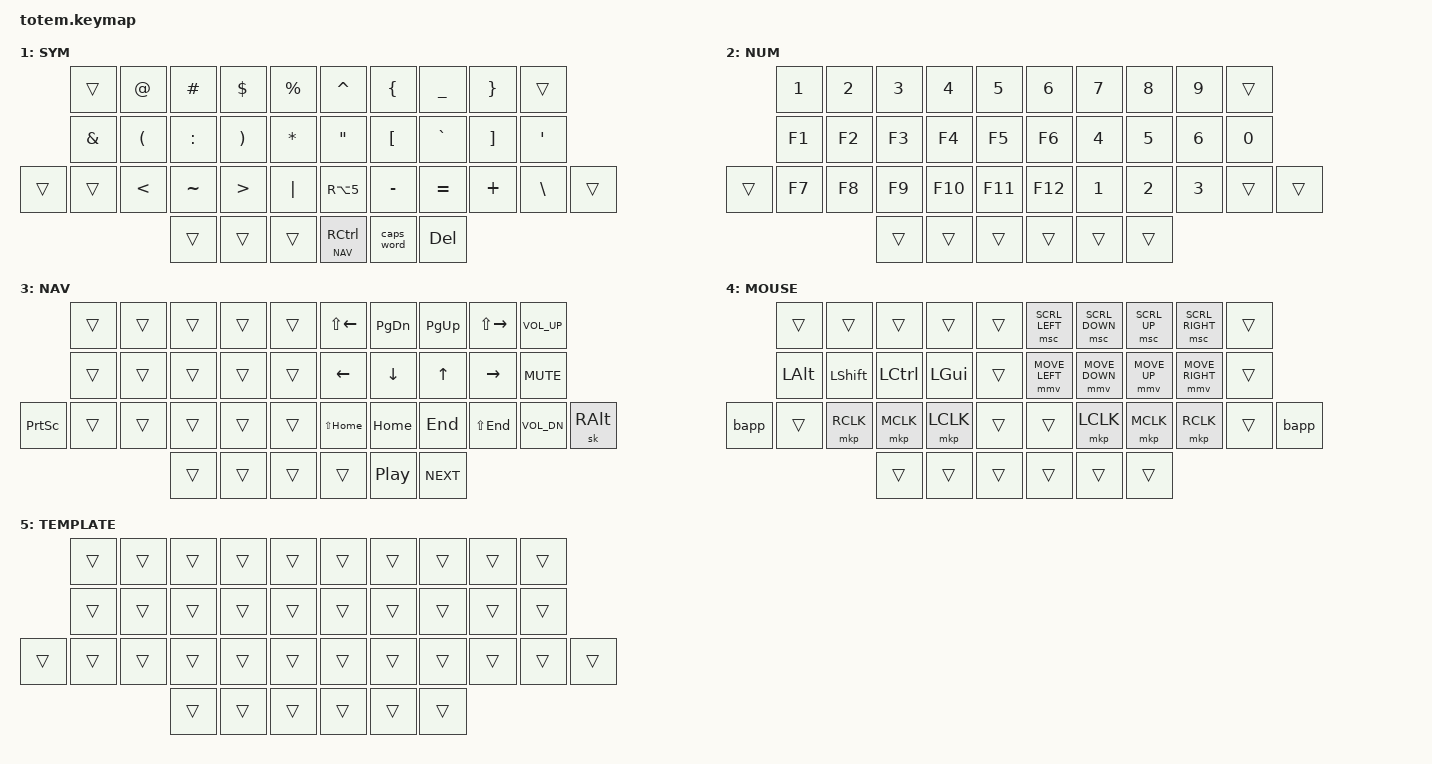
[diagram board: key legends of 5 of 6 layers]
/*
       ▀▀▀▀▀     ▀▀▀▀▀          ▀▀█▀▀
       ▄▀▀▀▄  ▄  ▄▀▀▀▄  ▄  ▄▀▀▀▄  █  ▄▀▀▀▄
       █   █  █  █   █  █  █   █  █  █   █
        ▀▀▀   █   ▀▀▀   █   ▀▀▀   ▀   ▀▀▀
              █      ▄▄▄█▄▄▄    █   █
              ▀      █  █  █     █▄█
            ▀▀▀▀▀    █  █  █      ▀
                     ▀  ▀  ▀
*/
#define ZMK_POINTING_DEFAULT_MOVE_VAL 1000  // default: 600
#define ZMK_POINTING_DEFAULT_SCRL_VAL 20    // default: 10

#include <behaviors.dtsi>
#include <dt-bindings/zmk/keys.h>
#include <dt-bindings/zmk/bt.h>
#include <dt-bindings/zmk/pointing.h>
#include <behaviors/battery_percentage_printer.dtsi>

#define VALMAK 0
#define SYM 1
#define NUM 2
#define NAV 3
#define MOUSE 4

#define XXX &none
#define ___ &trans

#define KEYS_L 0 1 2 3 4 10 11 12 13 14 20 21 22 23 24 25
#define KEYS_R 5 6 7 8 9 15 16 17 18 19 26 27 28 29 30 31
#define THUMBS_L 32 33 34
#define THUMBS_R 35 36 37
#define THUMBS THUMBS_L THUMBS_R

#define H1 LGUI
#define H2 LCTRL
#define H3 LSHFT
#define H4 LALT
#define H5 RALT
#define HRML(k1, k2, k3, k4) &hl H4 k1  &hl H3 k2  &hl H2 k3 &hl H1 k4
#define HRMR(k1, k2, k3, k4) &hr H1 k1  &hr H2 k2  &hr H3 k3 &hr H4 k4

#define QUICK_TAP_MS 200

/ {
    behaviors {
        comma: comma_morph {
            compatible = "zmk,behavior-mod-morph";
            #binding-cells = <0>;
            mods = <(MOD_LSFT | MOD_RSFT)>;
            bindings = <&kp COMMA>, <&kp SEMI>;
        };
        dot: dot_morph {
            compatible = "zmk,behavior-mod-morph";
            #binding-cells = <0>;
            mods = <(MOD_LSFT | MOD_RSFT)>;
            bindings = <&kp DOT>, <&kp QMARK>;
        };
        slash: slash_morph {
            compatible = "zmk,behavior-mod-morph";
            #binding-cells = <0>;
            mods = <(MOD_LSFT | MOD_RSFT)>;
            bindings = <&kp SLASH>, <&kp EXCL>;
        };
        skq: sticky_key_quick {
            compatible = "zmk,behavior-sticky-key";
            bindings = <&kp>;
            #binding-cells = <1>;
            quick-release; // release after the next key is pressed, not released
            release-after-ms = <1000>;
        };

        // hl and hr reuse the same settings, just hold-trigger-key-positions are different
        hl: home_row_mod_l {
            compatible = "zmk,behavior-hold-tap";
            #binding-cells = <2>;
            bindings = <&kp>, <&kp>;
            flavor = "balanced";
            tapping-term-ms = <280>;
            quick-tap-ms = <QUICK_TAP_MS>;
            require-prior-idle-ms = <200>;
            hold-trigger-on-release;
            hold-trigger-key-positions = <KEYS_R THUMBS>;
        };
        hr: home_row_mod_r {
            compatible = "zmk,behavior-hold-tap";
            #binding-cells = <2>;
            bindings = <&kp>, <&kp>;
            flavor = "balanced";
            tapping-term-ms = <280>;
            quick-tap-ms = <QUICK_TAP_MS>;
            require-prior-idle-ms = <200>;
            hold-trigger-on-release;
            hold-trigger-key-positions = <KEYS_L THUMBS>;
        };
        // regular thumb layer switch
        tl: thumb_layer_l {
            compatible = "zmk,behavior-hold-tap";
            #binding-cells = <2>;
            bindings = <&mo>, <&kp>;
            flavor = "hold-preferred";
            tapping-term-ms = <200>;
            quick-tap-ms = <QUICK_TAP_MS>;
            hold-trigger-key-positions = <KEYS_L KEYS_R THUMBS_R>;
        };
        tr: thumb_layer_r {
            compatible = "zmk,behavior-hold-tap";
            #binding-cells = <2>;
            bindings = <&mo>, <&kp>;
            flavor = "hold-preferred";
            tapping-term-ms = <200>;
            quick-tap-ms = <QUICK_TAP_MS>;
            hold-trigger-key-positions = <KEYS_L KEYS_R THUMBS_L>;
        };
        trr: thumb_layer_alpha_r {
            compatible = "zmk,behavior-hold-tap";
            #binding-cells = <2>;
            bindings = <&mo>, <&kp>;
            flavor = "balanced";
            tapping-term-ms = <200>;
            quick-tap-ms = <QUICK_TAP_MS>;
            require-prior-idle-ms = <100>;
            hold-trigger-key-positions = <KEYS_L KEYS_R THUMBS_L>;
        };
        // tls is a special thumb layer version that includes capital space to end a sentence and has alpha-like hrm
        // timings too
        tls: thumb_layer_spc {
            compatible = "zmk,behavior-hold-tap";
            #binding-cells = <2>;
            bindings = <&mo>, <&spc_morph>;
            flavor = "balanced";
            tapping-term-ms = <200>;
            quick-tap-ms = <QUICK_TAP_MS>;
            require-prior-idle-ms = <100>;
            hold-trigger-key-positions = <KEYS_L KEYS_R THUMBS_R>;
        };
        dot_spc: dot_space {
            compatible = "zmk,behavior-macro";
            #binding-cells = <0>;
            bindings = <&kp DOT &kp SPACE &skq LSHFT>;
            wait-ms = <0>;
            tap-ms = <5>;
        };
        spc_morph: space_morph {
            compatible = "zmk,behavior-mod-morph";
            #binding-cells = <0>;
            mods = <(MOD_LSFT | MOD_RSFT)>;
            bindings = <&kp SPACE>, <&dot_spc>;
        };
    };

    mt {
        flavor = "balanced";
        tapping-term-ms = <240>;
        quick-tap-ms = <QUICK_TAP_MS>;
    };

    lt {
        flavor = "balanced";
        tapping-term-ms = <240>;
        quick-tap-ms = <QUICK_TAP_MS>;
    };

    combos {
        compatible = "zmk,combos";
        /* ┌────────────────────┬────────────────────┐
           │  0   1   2   3   4 │  5   6   7   8   9 │
        ┌──┘ 10  11  12  13  14 │ 15  16  17  18  19 └───┐
        │ 20 21  22  23  24  25 │ 26  27  28  29  30  31 │
        └──────────┐ 32  33  34 │ 35  36  37 ┌───────────┘
                   └────────────┴────────────┘ */
        /* combo_repeat { */
        /*     timeout-ms = <100>; */
        /*     key-positions = <34 35>; */
        /*     bindings = <&key_repeat>; */
        /* }; */
        /* combo_bspc { */
        /*     timeout-ms = <30>; */
        /*     key-positions = <16 17>; */
        /*     bindings = <&kp BSPC>; */
        /* }; */
        /* combo_ret { */
        /*     timeout-ms = <30>; */
        /*     key-positions = <17 18>; */
        /*     bindings = <&kp RET>; */
        /* }; */
        /* combo_tab { */
        /*     timeout-ms = <30>; */
        /*     key-positions = <12 13>; */
        /*     bindings = <&kp TAB>; */
        /* }; */
        /* combo_esc { */
        /*     timeout-ms = <30>; */
        /*     key-positions = <11 12>; */
        /*     bindings = <&kp ESC>; */
        /* }; */
        combo_toggle_valmak {
            timeout-ms = <50>;
            key-positions = <20 31>;
            bindings = <&tog VALMAK>;
            layers = <0 1 2 3 4 5>;
        };
    };

    conditional_layers {
        compatible = "zmk,conditional-layers";
        tri_layer {
            if-layers = <SYM NAV>;
            then-layer = <MOUSE>;
        };
    };

    keymap {
        compatible = "zmk,keymap";

        VALMAK {
            display-name = "VALMAK";
            bindings = <
        //           ┌──────────┬──────────┬──────────┬──────────┬──────────┐   ┌──────────┬──────────┬──────────┬──────────┬──────────┐
        //           │    Q     │    W     │    F     │    P     │    B     │   │    TAB   │    U     │    O     │    Y     │    J     │
                      &kp Q      &kp W      &kp F      &kp P      &kp B          &kp TAB    &kp U      &kp O      &kp Y      &kp J
        //           ├──────────┼──────────┼──────────┼──────────┼──────────┤   ├──────────┼──────────┼──────────┼──────────┼──────────┤
        //           │    N     │    L     │    S     │    T     │    G     │   │  ENTER   │    E     │    A     │    I     │    H     │
                     HRML(N,         L,         S,         T)     &kp G          &kp RET   HRMR(E,         A,         I,         H)
        //┌──────────┼──────────┼──────────┼──────────┼──────────┼──────────┤   ├──────────┼──────────┼──────────┼──────────┼──────────┼──────────┐
        //│    X     │    Z     │    M     │    C     │    D     │    V     │   │    -     │    '     │   , ;    │   . ?    │    / !   │    K     │
           &kp X      &kp Z      &kp M      &kp C      &kp D      &kp V          &kp MINUS  &kp SQT    &comma     &dot       &slash    &kp K
        //└──────────┴──────────┴──────────┼──────────┼──────────┼──────────┤   ├──────────┼──────────┼──────────┼──────────┴──────────┴──────────┘
        //                                 │TRANS/MIC │ NUM/ESC  │SYM/SPACE │   │  NAV/R   │  SHIFT   │BACKSPACE │
                                           &hl F13 F20 &lt NUM ESC &tls SYM 0    &trr NAV R  &skq LSHFT &kp BSPC
        //                                 └──────────┴──────────┴──────────┘   └──────────┴──────────┴──────────┘
            >;
        };

        SYM {
            display-name = "SYM";
            bindings = <
        //           ┌──────────┬──────────┬──────────┬──────────┬──────────┐   ┌──────────┬──────────┬──────────┬──────────┬──────────┐
        //           │          │    @     │    #     │    $     │    %     │   │    ^     │    {     │    _     │    }     │          │
                         ___     &kp AT     &kp HASH   &kp DLLR   &kp PRCNT      &kp CARET  &kp LBRC   &kp UNDER  &kp RBRC      ___
        //           ├──────────┼──────────┼──────────┼──────────┼──────────┤   ├──────────┼──────────┼──────────┼──────────┼──────────┤
        //           │    &     │    (     │    :     │    )     │    *     │   │    "     │    [     │    `     │    ]     │    '     │
                      &kp AMPS   &kp LPAR   &kp COLON  &kp RPAR   &kp ASTRK      &kp DQT    &kp LBKT   &kp GRAVE  &kp RBKT   &kp SQT
        //┌──────────┼──────────┼──────────┼──────────┼──────────┼──────────┤   ├──────────┼──────────┼──────────┼──────────┼──────────┼──────────┐
        //│          │          │    <     │    ~     │    >     │    |     │   │    €     │    -     │    =     │    +     │    \     │          │
              ___        ___     &kp LT     &kp TILDE  &kp GT     &kp PIPE       &kp RA(N5) &kp MINUS  &kp EQUAL  &kp PLUS   &kp BSLH      ___
        //└──────────┴──────────┴──────────┼──────────┼──────────┼──────────┤   ├──────────┼──────────┼──────────┼──────────┴──────────┴──────────┘
        //                                 │          │          │          │   │ NAV/COMP │  caps    │  DELETE  │
                                               ___        ___        ___      &tr NAV RCTRL &caps_word &kp DEL
        //                                 └──────────┴──────────┴──────────┘   └──────────┴──────────┴──────────┘
            >;
        };

        NUM {
            display-name = "NUM";
            bindings = <
        //           ┌──────────┬──────────┬──────────┬──────────┬──────────┐   ┌──────────┬──────────┬──────────┬──────────┬──────────┐
        //           │    1     │    2     │    3     │    4     │    5     │   │    6     │    7     │    8     │    9     │          │
                      &kp N1     &kp N2     &kp N3     &kp N4     &kp N5         &kp N6     &kp N7     &kp N8     &kp N9         ___
        //           ├──────────┼──────────┼──────────┼──────────┼──────────┤   ├──────────┼──────────┼──────────┼──────────┼──────────┤
        //           │    F1    │    F2    │    F3    │    F4    │    F5    │   │    F6    │    4     │    5     │    6     │     0    │
                      &kp F1     &kp F2     &kp F3     &kp F4     &kp F5         &kp F6     &kp N4     &kp N5     &kp N6     &kp N0
        //┌──────────┼──────────┼──────────┼──────────┼──────────┼──────────┤   ├──────────┼──────────┼──────────┼──────────┼──────────┼──────────┐
        //│          │    F7    │    F8    │    F9    │    F10   │    F11   │   │    F12   │    1     │    2     │    3     │          │          │
              ___     &kp F7     &kp F8     &kp F9     &kp F10    &kp F11        &kp F12    &kp N1     &kp N2     &kp N3        ___        ___
        //└──────────┴──────────┴──────────┼──────────┼──────────┼──────────┤   ├──────────┼──────────┼──────────┼──────────┴──────────┴──────────┘
        //                                 │          │          │          │   │          │          │          │
                                               ___        ___        ___            ___        ___        ___
        //                                 └──────────┴──────────┴──────────┘   └──────────┴──────────┴──────────┘
            >;
        };

        // NUM {
        //     display-name = "NUM";
        //     bindings = <
        // //           ┌──────────┬──────────┬──────────┬──────────┬──────────┐   ┌──────────┬──────────┬──────────┬──────────┬──────────┐
        // //           │          │          │          │          │          │   │    +     │    7     │    8     │    9     │    =     │
        //                  ___        ___        ___        ___        ___         &kp PLUS   &kp N7     &kp N8     &kp N9     &kp EQUAL
        // //           ├──────────┼──────────┼──────────┼──────────┼──────────┤   ├──────────┼──────────┼──────────┼──────────┼──────────┤
        // //           │          │          │          │          │          │   │    -     │    4     │    5     │    6     │    0     │
        //                  ___        ___        ___        ___        ___         &kp MINUS  &kp N4     &kp N5     &kp N6     &kp N0
        // //┌──────────┼──────────┼──────────┼──────────┼──────────┼──────────┤   ├──────────┼──────────┼──────────┼──────────┼──────────┼──────────┐
        // //│          │          │          │          │          │          │   │    .     │    1     │    2     │    3     │    /     │    *     │
        //       ___        ___        ___        ___        ___        ___         &kp DOT    &kp N1     &kp N2     &kp N3     &kp SLASH  &kp ASTRK
        // //└──────────┴──────────┴──────────┼──────────┼──────────┼──────────┤   ├──────────┼──────────┼──────────┼──────────┴──────────┴──────────┘
        // //                                 │          │          │          │   │          │          │          │
        //                                        ___        ___        ___            ___        ___        ___
        // //                                 └──────────┴──────────┴──────────┘   └──────────┴──────────┴──────────┘
        //     >;
        // };

        NAV {
            display-name = "NAV";
            bindings = <
        //           ┌──────────┬──────────┬──────────┬──────────┬──────────┐   ┌──────────┬──────────┬──────────┬──────────┬──────────┐
        //           │          │          │          │          │          │   │          │    ⮮     │    ⮭     │          │    🕪     │
                         ___        ___        ___        ___        ___       &kp LS(LEFT) &kp PG_DN  &kp PG_UP &kp LS(RIGHT) &kp C_VOL_UP
        //           ├──────────┼──────────┼──────────┼──────────┼──────────┤   ├──────────┼──────────┼──────────┼──────────┼──────────┤
        //           │          │          │          │          │          │   │    ⮜     │    ⮟     │    ⮝     │    ⮞     │ vol mute │
                         ___        ___        ___        ___        ___         &kp LEFT   &kp DOWN   &kp UP     &kp RIGHT  &kp C_MUTE
        //┌──────────┼──────────┼──────────┼──────────┼──────────┼──────────┤   ├──────────┼──────────┼──────────┼──────────┼──────────┼──────────┐
        //│          │          │          │          │          │          │   │  S-HOME  │    ⮪     │    ⮫     │  S-END   │    🕩     │   RALT   │
           &kp PSCRN     ___        ___        ___        ___        ___       &kp LS(HOME)  &kp HOME   &kp END   &kp LS(END) &kp C_VOL_DN &sk RALT
        //└──────────┴──────────┴──────────┼──────────┼──────────┼──────────┤   ├──────────┼──────────┼──────────┼──────────┴──────────┴──────────┘
        //                                 │          │          │          │   │          │    ⏵     │    ⏭     │
                                               ___        ___        ___            ___     &kp C_PP   &kp C_NEXT
        //                                 └──────────┴──────────┴──────────┘   └──────────┴──────────┴──────────┘
            >;
        };

        MOUSE {
            display-name = "MOUSE";
            bindings = <
        //           ┌──────────┬──────────┬──────────┬──────────┬──────────┐   ┌──────────┬──────────┬──────────┬──────────┬──────────┐
        //           │          │          │          │          │          │   │          │          │          │          │          │
                         ___        ___        ___        ___        ___      &msc SCRL_LEFT &msc SCRL_DOWN &msc SCRL_UP &msc SCRL_RIGHT ___
        //           ├──────────┼──────────┼──────────┼──────────┼──────────┤   ├──────────┼──────────┼──────────┼──────────┼──────────┤
        //           │          │          │          │          │          │   │          │          │          │          │          │
                      &kp LALT   &kp LSHFT  &kp LCTRL  &kp LGUI      ___      &mmv MOVE_LEFT &mmv MOVE_DOWN &mmv MOVE_UP &mmv MOVE_RIGHT ___
        //┌──────────┼──────────┼──────────┼──────────┼──────────┼──────────┤   ├──────────┼──────────┼──────────┼──────────┼──────────┼──────────┐
        //│          │          │          │          │          │          │   │          │          │          │          │          │          │
             &bapp       ___     &mkp RCLK  &mkp MCLK  &mkp LCLK     ___            ___     &mkp LCLK  &mkp MCLK  &mkp RCLK     ___       &bapp
        //└──────────┴──────────┴──────────┼──────────┼──────────┼──────────┤   ├──────────┼──────────┼──────────┼──────────┴──────────┴──────────┘
        //                                 │          │          │          │   │          │          │          │
                                               ___        ___        ___            ___        ___        ___
        //                                 └──────────┴──────────┴──────────┘   └──────────┴──────────┴──────────┘
            >;
        };

        9 {
            display-name = "TEMPLATE";
            bindings = <
        //           ┌──────────┬──────────┬──────────┬──────────┬──────────┐   ┌──────────┬──────────┬──────────┬──────────┬──────────┐
        //           │          │          │          │          │          │   │          │          │          │          │          │
                         ___        ___        ___        ___        ___            ___        ___        ___        ___        ___
        //           ├──────────┼──────────┼──────────┼──────────┼──────────┤   ├──────────┼──────────┼──────────┼──────────┼──────────┤
        //           │          │          │          │          │          │   │          │          │          │          │          │
                         ___        ___        ___        ___        ___            ___        ___        ___        ___        ___
        //┌──────────┼──────────┼──────────┼──────────┼──────────┼──────────┤   ├──────────┼──────────┼──────────┼──────────┼──────────┼──────────┐
        //│          │          │          │          │          │          │   │          │          │          │          │          │          │
              ___        ___        ___        ___        ___        ___            ___        ___        ___        ___        ___        ___
        //└──────────┴──────────┴──────────┼──────────┼──────────┼──────────┤   ├──────────┼──────────┼──────────┼──────────┴──────────┴──────────┘
        //                                 │          │          │          │   │          │          │          │
                                               ___        ___        ___            ___        ___        ___
        //                                 └──────────┴──────────┴──────────┘   └──────────┴──────────┴──────────┘
            >;
        };
    };
};
